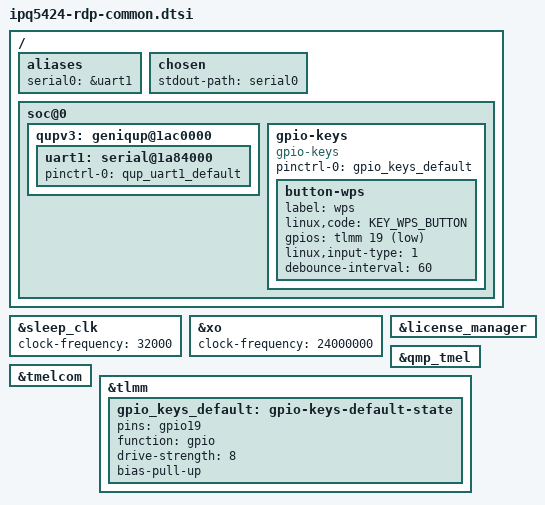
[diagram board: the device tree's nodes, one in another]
// SPDX-License-Identifier: (GPL-2.0+ OR BSD-3-Clause)
/*
 * IPQ5424 RDP board common device tree source
 *
 * Copyright (c) 2020-2021 The Linux Foundation. All rights reserved.
 * Copyright (c) 2022-2024 Qualcomm Innovation Center, Inc. All rights reserved.
 */

/dts-v1/;

#include <dt-bindings/gpio/gpio.h>
#include <dt-bindings/input/input.h>
#include <dt-bindings/leds/common.h>
#include "ipq5424.dtsi"

/ {
	aliases {
		serial0 = &uart1;
	};

	chosen {
		stdout-path = "serial0";
	};

	soc@0 {
		qupv3: geniqup@1ac0000 {
			status = "okay";

			uart1: serial@1a84000 {
				pinctrl-0 = <&qup_uart1_default>;
				pinctrl-names = "default";
				status = "okay";
			};
		};

		gpio-keys {
			compatible = "gpio-keys";
			pinctrl-0 = <&gpio_keys_default>;
			pinctrl-names = "default";
			status = "okay";

			button-wps {
				label = "wps";
				linux,code = <KEY_WPS_BUTTON>;
				gpios = <&tlmm 19 GPIO_ACTIVE_LOW>;
				linux,input-type = <1>;
				debounce-interval = <60>;
			};
		};
	};
};

&sleep_clk {
	clock-frequency = <32000>;
};

&xo {
	clock-frequency = <24000000>;
};

&license_manager {
	status = "okay";
};

&qmp_tmel {
	status = "okay";
};

&tmelcom {
	status = "okay";
};

&tlmm {
	gpio_keys_default: gpio-keys-default-state {
		pins = "gpio19";
		function = "gpio";
		drive-strength = <8>;
		bias-pull-up;
	};
};
